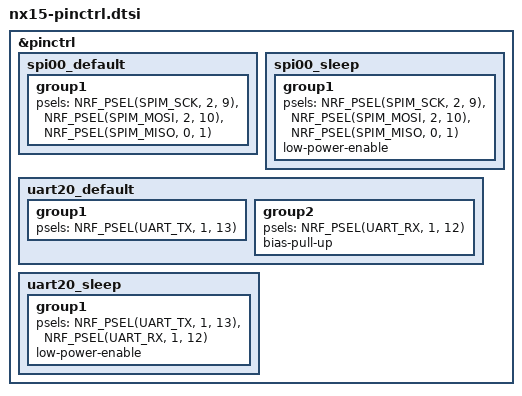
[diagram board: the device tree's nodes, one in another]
/*
 * Copyright (c) 2026 Korlinx
 *
 * SPDX-License-Identifier: Apache-2.0
 */

&pinctrl {
	spi00_default: spi00_default {
		group1 {
			psels = <NRF_PSEL(SPIM_SCK, 2, 9)>,
				<NRF_PSEL(SPIM_MOSI, 2, 10)>,
				<NRF_PSEL(SPIM_MISO, 0, 1)>;
		};
	};

	spi00_sleep: spi00_sleep {
		group1 {
			psels = <NRF_PSEL(SPIM_SCK, 2, 9)>,
				<NRF_PSEL(SPIM_MOSI, 2, 10)>,
				<NRF_PSEL(SPIM_MISO, 0, 1)>;
			low-power-enable;
		};
	};

	uart20_default: uart20_default {
		group1 {
			psels = <NRF_PSEL(UART_TX, 1, 13)>;
		};
		group2 {
			psels = <NRF_PSEL(UART_RX, 1, 12)>;
			bias-pull-up;
		};
	};

	uart20_sleep: uart20_sleep {
		group1 {
			psels = <NRF_PSEL(UART_TX, 1, 13)>,
				<NRF_PSEL(UART_RX, 1, 12)>;
			low-power-enable;
		};
	};
};
